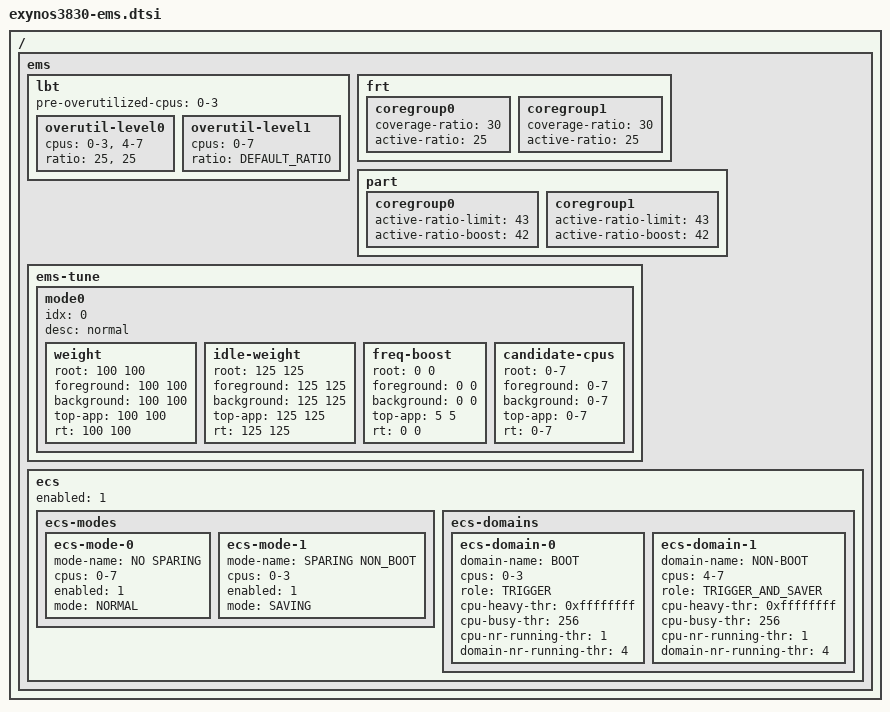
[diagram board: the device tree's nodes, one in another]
/*
 * SAMSUNG EXYNOS SoC EMS device tree source
 *
 * Copyright (c) 2019 Samsung Electronics Co., Ltd.
 *		http://www.samsung.com
 *
 * SAMSUNG EXYNOS SoC EMS device nodes are listed in this file.
 * EXYNOS based board files should include this file.
 *
 * This program is free software; you can redistribute it and/or modify
 * it under the terms of the GNU General Public License version 2 as
 * published by the Free Software Foundation.
 *
 */

/ {
	ems {
		/* Load Balance Trigger */
		#define DEFAULT_RATIO	80
		lbt {
			pre-overutilized-cpus = "0-3";

			overutil-level0 {
				cpus =	"0-3",
					"4-7";
				ratio =	<25>,
					<25>;
			};
			overutil-level1 {
				cpus = "0-7";
				ratio = <DEFAULT_RATIO>;
			};
		};

		/* FRT Migration */
		frt {
			coregroup0 {
				coverage-ratio = <30>;
				active-ratio = <25>;
			};
			coregroup1 {
				coverage-ratio = <30>;
				active-ratio = <25>;
			};
		};

		part {
			coregroup0 {
				active-ratio-limit = <43>;
				active-ratio-boost = <42>;
			};
			coregroup1 {
				active-ratio-limit = <43>;
				active-ratio-boost = <42>;
			};
		};

                ems-tune {
                        mode0 {
                                idx = <0>;
                                desc = "normal";

                                /* weight (%) applied to active core's efficiency */
                                weight {                /* CL0 CL1 */
                                        root            = <100 100>;
                                        foreground      = <100 100>;
                                        background      = <100 100>;
                                        top-app         = <100 100>;
                                        rt              = <100 100>;
                                };

                                /* weight (%) applied to idle core's efficiency */
                                idle-weight {           /* CL0 CL1 */
                                        root            = <125 125>;
                                        foreground      = <125 125>;
                                        background      = <125 125>;
                                        top-app         = <125 125>;
                                        rt              = <125 125>;
                                };

                                /* Boosting margin applied to frequency selection */
                                freq-boost {            /* CL0 CL1 */
                                        root            = <  0   0>;
                                        foreground      = <  0   0>;
                                        background      = <  0   0>;
                                        top-app         = <  5   5>;
                                        rt              = <  0   0>;
                                };

                                /* candidate cpus applied to core selection */
                                candidate-cpus {
                                        root            = "0-7";
                                        foreground      = "0-7";
                                        background      = "0-7";
                                        top-app         = "0-7";
                                        rt              = "0-7";
                                };
                        };
		};

		ecs {
			enabled = <1>;

			ecs-modes {
				ecs-mode-0 {
					mode-name = "NO SPARING";
					cpus = "0-7";
					enabled = <1>;
					mode = <NORMAL>;
				};
				ecs-mode-1 {
					mode-name = "SPARING NON_BOOT";
					cpus = "0-3";
					enabled = <1>;
					mode = <SAVING>;
				};
			};

			ecs-domains {
				ecs-domain-0 {
					domain-name = "BOOT";
					cpus = "0-3";
					role = <TRIGGER>;
					cpu-heavy-thr = <0xffffffff>;
					cpu-busy-thr = <256>;
					cpu-nr-running-thr = <1>;
					domain-nr-running-thr = <4>;
				};
				ecs-domain-1 {
					domain-name = "NON-BOOT";
					cpus = "4-7";
					role = <TRIGGER_AND_SAVER>;
					cpu-heavy-thr = <0xffffffff>;
					cpu-busy-thr = <256>;
					cpu-nr-running-thr = <1>;
					domain-nr-running-thr = <4>;
				};
			};
		};
	};
};
